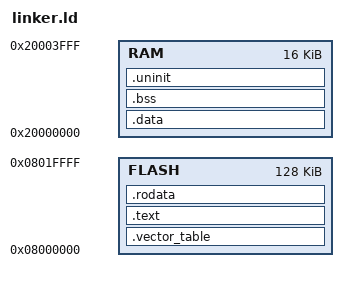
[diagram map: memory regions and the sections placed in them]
MEMORY
{
  RAM   : ORIGIN  = 0x20000000, LENGTH = 16K
  FLASH : ORIGIN  = 0x08000000, LENGTH = 128K
}

EXTERN(__RESET_VECTOR);

/* ? */

/* # Sections */
SECTIONS
{
  PROVIDE(_stack_start = ORIGIN(RAM) + LENGTH(RAM));

  /* ## Sections in FLASH */
  /* ### Vector table */
  .vector_table ORIGIN(FLASH) :
  {
    . = 0x08000004;
    /* Reset vector */
    KEEP(*(.vector_table.reset_vector)); /* this is the `__RESET_VECTOR` symbol */

    /* Placeholder for other unused interrupts in the vector table.
   
     * This doesn't actually PUT anything here, which would be bad
     * if we ever used interrupts or hit a fault, which we don't,
     * in our example.
     */
    . = 0x080000C0;
  } > FLASH

  PROVIDE(_stext = ADDR(.vector_table) + SIZEOF(.vector_table));

  /* ### .text */
  .text _stext :
  {
    *(.text .text.*);
    . = ALIGN(4);
    __etext = .;
  } > FLASH

  /* ### .rodata */
  .rodata __etext : ALIGN(4)
  {
    *(.rodata .rodata.*);

    /* 4-byte align the end (VMA) of this section.
       This is required by LLD to ensure the LMA of the following .data
       section will have the correct alignment. */
    . = ALIGN(4);
    __erodata = .;
  } > FLASH

  /* ## Sections in RAM */
  /* ### .data */
  .data : AT(__erodata) ALIGN(4)
  {
    . = ALIGN(4);
    __sdata = .;
    *(.data .data.*);
    . = ALIGN(4); /* 4-byte align the end (VMA) of this section */
    __edata = .;
  } > RAM

  /* LMA of .data */
  __sidata = LOADADDR(.data);

  /* ### .bss */
  .bss : ALIGN(4)
  {
    . = ALIGN(4);
    __sbss = .;
    *(.bss .bss.*);
    . = ALIGN(4); /* 4-byte align the end (VMA) of this section */
    __ebss = .;
  } > RAM

  /* ### .uninit */
  .uninit (NOLOAD) : ALIGN(4)
  {
    . = ALIGN(4);
    *(.uninit .uninit.*);
    . = ALIGN(4);
  } > RAM

  /* Place the heap right after `.uninit` */
  . = ALIGN(4);
  __sheap = .;

  /* ## Discarded sections */
  /DISCARD/ :
  {
    /* Unused exception related info that only wastes space */
    *(.ARM.exidx);
    *(.ARM.exidx.*);
    *(.ARM.extab.*);
  }
}
